# DA14531 register map
Vendor: Dialog; Series: DA14531; File version: 1.2
CPU: CM0 r1p0, little endian, MPU, FPU, 3 interrupt priority bits
Registers are 16-bit, read-write, reset 0x0 unless marked. A register's access mark holds for its fields unless they carry their own. Offsets are from the block's base; [hi:lo] are bit positions.

## adplldig — adplldig registers
Base 0x40003000
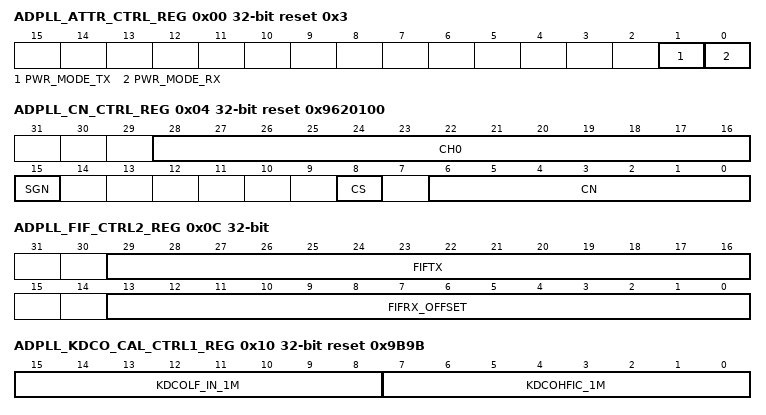
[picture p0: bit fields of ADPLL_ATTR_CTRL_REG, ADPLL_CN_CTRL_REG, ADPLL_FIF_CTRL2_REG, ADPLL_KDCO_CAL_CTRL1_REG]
0x00 ADPLL_ATTR_CTRL_REG 32-bit reset 0x3
  [1] PWR_MODE_TX, [0] PWR_MODE_RX
0x04 ADPLL_CN_CTRL_REG 32-bit reset 0x9620100
  [28:16] CH0, [15] SGN, [8] CS, [6:0] CN
0x08 ADPLL_FIF_CTRL1_REG 32-bit reset 0x400
  [13:0] FIFRX_1M
0x0C ADPLL_FIF_CTRL2_REG 32-bit
  [29:16] FIFTX, [13:0] FIFRX_OFFSET
0x10 ADPLL_KDCO_CAL_CTRL1_REG 32-bit reset 0x9B9B
  [15:8] KDCOLF_IN_1M, [7:0] KDCOHFIC_1M
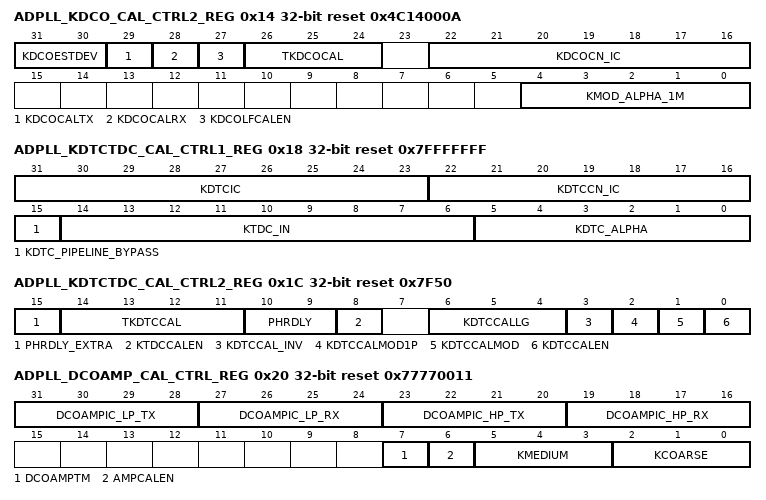
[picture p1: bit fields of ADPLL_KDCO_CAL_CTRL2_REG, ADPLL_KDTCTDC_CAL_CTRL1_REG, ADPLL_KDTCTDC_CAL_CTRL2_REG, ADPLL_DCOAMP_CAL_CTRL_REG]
0x14 ADPLL_KDCO_CAL_CTRL2_REG 32-bit reset 0x4C14000A (reset mask 0x7FFFFFFF)
  [31:30] KDCOESTDEV, [29] KDCOCALTX, [28] KDCOCALRX, [27] KDCOLFCALEN, [26:24] TKDCOCAL, [22:16] KDCOCN_IC, [4:0] KMOD_ALPHA_1M
0x18 ADPLL_KDTCTDC_CAL_CTRL1_REG 32-bit reset 0x7FFFFFFF (reset mask 0x7FFFFFFF)
  [31:23] KDTCIC, [22:16] KDTCCN_IC, [15] KDTC_PIPELINE_BYPASS, [14:6] KTDC_IN, [5:0] KDTC_ALPHA
0x1C ADPLL_KDTCTDC_CAL_CTRL2_REG 32-bit reset 0x7F50
  [15] PHRDLY_EXTRA, [14:11] TKDTCCAL, [10:9] PHRDLY, [8] KTDCCALEN, [6:4] KDTCCALLG, [3] KDTCCAL_INV, [2] KDTCCALMOD1P, [1] KDTCCALMOD, [0] KDTCCALEN
0x20 ADPLL_DCOAMP_CAL_CTRL_REG 32-bit reset 0x77770011 (reset mask 0x7FFFFFFF)
  [31:28] DCOAMPIC_LP_TX, [27:24] DCOAMPIC_LP_RX, [23:20] DCOAMPIC_HP_TX, [19:16] DCOAMPIC_HP_RX, [7] DCOAMPTM, [6] AMPCALEN, [5:3] KMEDIUM, [2:0] KCOARSE
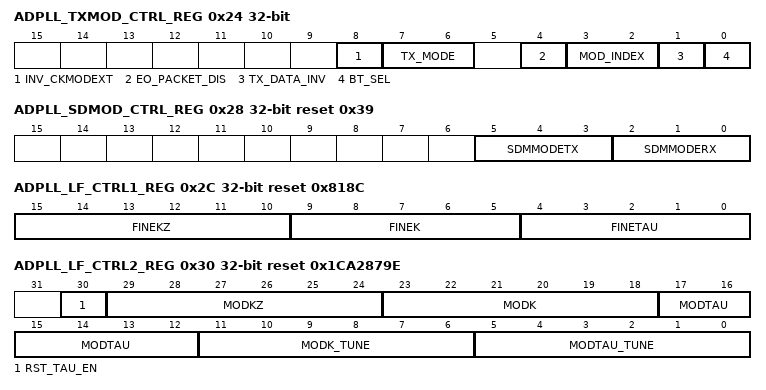
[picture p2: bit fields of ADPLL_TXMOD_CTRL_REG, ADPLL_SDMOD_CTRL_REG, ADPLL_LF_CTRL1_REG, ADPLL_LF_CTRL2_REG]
0x24 ADPLL_TXMOD_CTRL_REG 32-bit
  [8] INV_CKMODEXT, [7:6] TX_MODE, [4] EO_PACKET_DIS, [3:2] MOD_INDEX, [1] TX_DATA_INV, [0] BT_SEL
0x28 ADPLL_SDMOD_CTRL_REG 32-bit reset 0x39
  [5:3] SDMMODETX, [2:0] SDMMODERX
0x2C ADPLL_LF_CTRL1_REG 32-bit reset 0x818C
  [15:10] FINEKZ, [9:5] FINEK, [4:0] FINETAU
0x30 ADPLL_LF_CTRL2_REG 32-bit reset 0x1CA2879E
  [30] RST_TAU_EN, [29:24] MODKZ, [23:18] MODK, [17:12] MODTAU, [11:6] MODK_TUNE, [5:0] MODTAU_TUNE
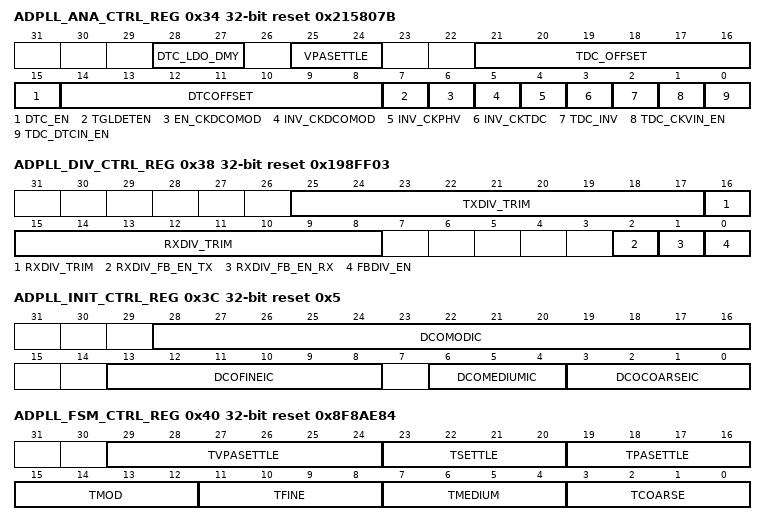
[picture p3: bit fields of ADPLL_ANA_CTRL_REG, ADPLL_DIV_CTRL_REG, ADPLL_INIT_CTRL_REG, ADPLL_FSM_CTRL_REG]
0x34 ADPLL_ANA_CTRL_REG 32-bit reset 0x215807B
  [28:27] DTC_LDO_DMY, [25:24] VPASETTLE, [21:16] TDC_OFFSET, [15] DTC_EN, [14:8] DTCOFFSET, [7] TGLDETEN, [6] EN_CKDCOMOD, [5] INV_CKDCOMOD, [4] INV_CKPHV, [3] INV_CKTDC, [2] TDC_INV, [1] TDC_CKVIN_EN, [0] TDC_DTCIN_EN
0x38 ADPLL_DIV_CTRL_REG 32-bit reset 0x198FF03
  [25:17] TXDIV_TRIM, [16:8] RXDIV_TRIM, [2] RXDIV_FB_EN_TX, [1] RXDIV_FB_EN_RX, [0] FBDIV_EN
0x3C ADPLL_INIT_CTRL_REG 32-bit reset 0x5
  [28:16] DCOMODIC, [13:8] DCOFINEIC, [6:4] DCOMEDIUMIC, [3:0] DCOCOARSEIC
0x40 ADPLL_FSM_CTRL_REG 32-bit reset 0x8F8AE84
  [29:24] TVPASETTLE, [23:20] TSETTLE, [19:16] TPASETTLE, [15:12] TMOD, [11:8] TFINE, [7:4] TMEDIUM, [3:0] TCOARSE
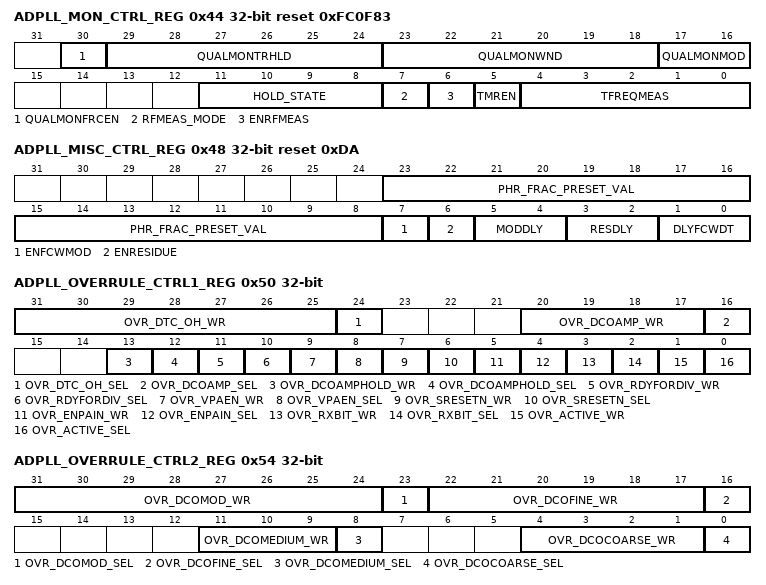
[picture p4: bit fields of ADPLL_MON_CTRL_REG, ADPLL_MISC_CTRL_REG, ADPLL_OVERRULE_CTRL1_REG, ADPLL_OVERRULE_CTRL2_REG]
0x44 ADPLL_MON_CTRL_REG 32-bit reset 0xFC0F83
  [30] QUALMONFRCEN, [29:24] QUALMONTRHLD, [23:18] QUALMONWND, [17:16] QUALMONMOD, [11:8] HOLD_STATE, [7] RFMEAS_MODE, [6] ENRFMEAS, [5] TMREN, [4:0] TFREQMEAS
0x48 ADPLL_MISC_CTRL_REG 32-bit reset 0xDA
  [23:8] PHR_FRAC_PRESET_VAL, [7] ENFCWMOD, [6] ENRESIDUE, [5:4] MODDLY, [3:2] RESDLY, [1:0] DLYFCWDT
0x50 ADPLL_OVERRULE_CTRL1_REG 32-bit (reset mask 0x7FFFFFFF)
  [31:25] OVR_DTC_OH_WR, [24] OVR_DTC_OH_SEL, [20:17] OVR_DCOAMP_WR, [16] OVR_DCOAMP_SEL, [13] OVR_DCOAMPHOLD_WR, [12] OVR_DCOAMPHOLD_SEL, [11] OVR_RDYFORDIV_WR, [10] OVR_RDYFORDIV_SEL, [9] OVR_VPAEN_WR, [8] OVR_VPAEN_SEL, [7] OVR_SRESETN_WR, [6] OVR_SRESETN_SEL, [5] OVR_ENPAIN_WR, [4] OVR_ENPAIN_SEL, [3] OVR_RXBIT_WR, [2] OVR_RXBIT_SEL, [1] OVR_ACTIVE_WR, [0] OVR_ACTIVE_SEL
0x54 ADPLL_OVERRULE_CTRL2_REG 32-bit (reset mask 0x7FFFFFFF)
  [31:24] OVR_DCOMOD_WR, [23] OVR_DCOMOD_SEL, [22:17] OVR_DCOFINE_WR, [16] OVR_DCOFINE_SEL, [11:9] OVR_DCOMEDIUM_WR, [8] OVR_DCOMEDIUM_SEL, [4:1] OVR_DCOCOARSE_WR, [0] OVR_DCOCOARSE_SEL
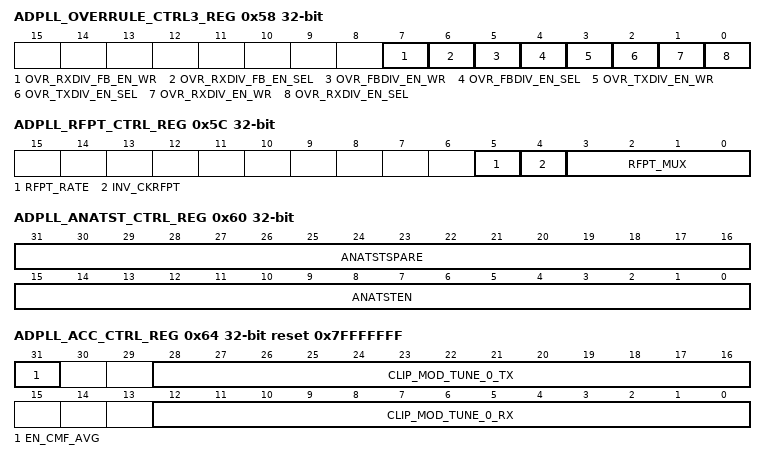
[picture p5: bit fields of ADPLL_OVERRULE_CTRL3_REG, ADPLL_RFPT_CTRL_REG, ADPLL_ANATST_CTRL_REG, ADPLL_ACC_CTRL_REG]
0x58 ADPLL_OVERRULE_CTRL3_REG 32-bit
  [7] OVR_RXDIV_FB_EN_WR, [6] OVR_RXDIV_FB_EN_SEL, [5] OVR_FBDIV_EN_WR, [4] OVR_FBDIV_EN_SEL, [3] OVR_TXDIV_EN_WR, [2] OVR_TXDIV_EN_SEL, [1] OVR_RXDIV_EN_WR, [0] OVR_RXDIV_EN_SEL
0x5C ADPLL_RFPT_CTRL_REG 32-bit
  [5] RFPT_RATE, [4] INV_CKRFPT, [3:0] RFPT_MUX
0x60 ADPLL_ANATST_CTRL_REG 32-bit (reset mask 0x7FFFFFFF)
  [31:16] ANATSTSPARE, [15:0] ANATSTEN
0x64 ADPLL_ACC_CTRL_REG 32-bit reset 0x7FFFFFFF (reset mask 0x7FFFFFFF)
  [31] EN_CMF_AVG, [28:16] CLIP_MOD_TUNE_0_TX, [12:0] CLIP_MOD_TUNE_0_RX
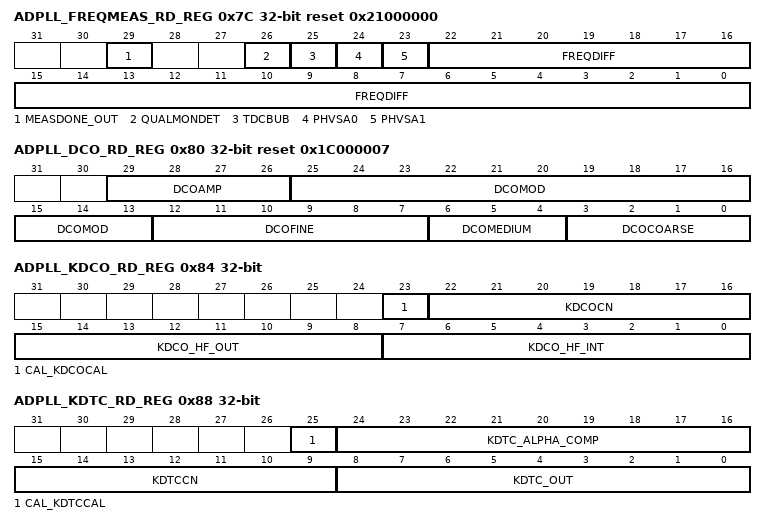
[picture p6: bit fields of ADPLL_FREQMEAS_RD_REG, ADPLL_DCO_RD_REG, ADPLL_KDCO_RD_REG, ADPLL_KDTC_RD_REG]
0x7C ADPLL_FREQMEAS_RD_REG 32-bit reset 0x21000000
  [29] MEASDONE_OUT ro, [26] QUALMONDET ro, [25] TDCBUB ro, [24] PHVSA0 ro, [23] PHVSA1 ro, [22:0] FREQDIFF ro
0x80 ADPLL_DCO_RD_REG 32-bit reset 0x1C000007
  [29:26] DCOAMP ro, [25:13] DCOMOD ro, [12:7] DCOFINE ro, [6:4] DCOMEDIUM ro, [3:0] DCOCOARSE ro
0x84 ADPLL_KDCO_RD_REG 32-bit
  [23] CAL_KDCOCAL ro, [22:16] KDCOCN ro, [15:8] KDCO_HF_OUT ro, [7:0] KDCO_HF_INT ro
0x88 ADPLL_KDTC_RD_REG 32-bit
  [25] CAL_KDTCCAL ro, [24:16] KDTC_ALPHA_COMP ro, [15:9] KDTCCN ro, [8:0] KDTC_OUT ro
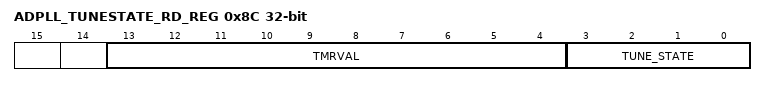
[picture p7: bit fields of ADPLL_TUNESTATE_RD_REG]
0x8C ADPLL_TUNESTATE_RD_REG 32-bit
  [13:4] TMRVAL ro, [3:0] TUNE_STATE ro
0x90 ADPLL_PLLFCWDT_RD_REG 32-bit reset 0x258800
  [22:0] PLLFCWDT ro
0x94 ADPLL_ANATST_RD_REG 32-bit
  [15:0] ANATSTSPARE_IN ro
